# VPFE0_VPFE register map
Vendor: Texas Instruments
Peripheral module from a debugger description file (folder J7ES).
Registers are 32-bit, read-write, reset 0x0 unless marked. A register's access mark holds for its fields unless they carry their own. Offsets are as the file gives them; lines under a group give offsets from that group; [hi:lo] are bit positions; {n}, {i} and the like mark numbered series; 'fields as' and 'values as' point back to an identical list; <NAME> marks a mode.

## VPFE0_VPFE
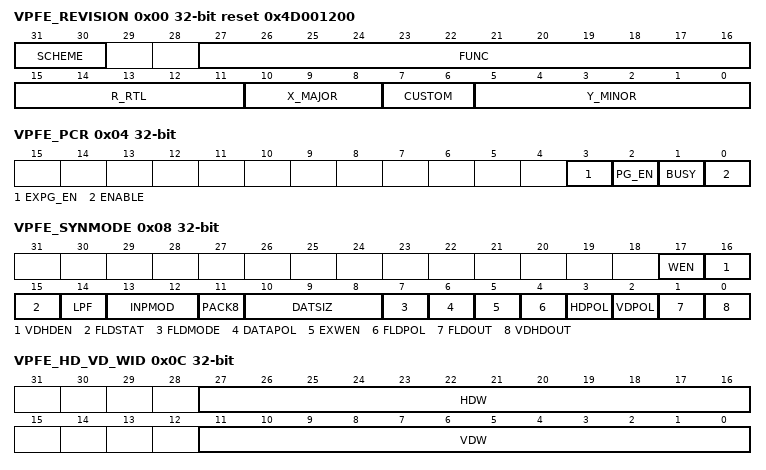
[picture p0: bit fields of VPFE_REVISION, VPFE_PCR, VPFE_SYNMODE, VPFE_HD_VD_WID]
0x00 VPFE_REVISION ro reset 0x4D001200 — IP Revision Identifier (X.Y.R) Used by software to track features, bugs, and compatibility
  [31:30] SCHEME — Used to distinguish between old scheme and current
  [27:16] FUNC — Function value
  [15:11] R_RTL — RTL Version [R], maintained by IP design owner
  [10:8] X_MAJOR — Major Revision [X], maintained by IP specification owner
  [7:6] CUSTOM — Custom version
  [5:0] Y_MINOR — Minor Revision [Y], maintained by IP specification owner
0x04 VPFE_PCR access per field — Peripheral Control Register
  [3] EXPG_EN rw — External pattern generator enable
  [2] PG_EN rw — Pattern generator enable
  [1] BUSY ro — VPFE busy bit 0h = Not busy 1h = Busy
  [0] ENABLE rw — This bit is latched by VD [start of frame] 0h = Disable 1h = Enable
0x08 VPFE_SYNMODE access per field — SYNC and Mode Set Register
  [17] WEN rw — Data write enable Controls whether or not input raw data is written to external memory This bit is latched by VD 0h = Disable 1h = Enable
  [16] VDHDEN rw — VD/HD enable Activates internal timing generator to synchronize with external VD/HD signals This bit should be set to 1 when HD and VD signals are used at any time 0h = Disable 1h = Enable
  [15] FLDSTAT ro — Field status Indicates the status of the current field when in interlaced mode 0h = Odd field 1h = Even field
  [14] LPF rw — 3-tap low-pass [anti-aliasing] filter This bit is latched by VD 0h = Off 1h = On
  [13:12] INPMOD rw — Setting data input mode 0h = Raw Data 1h = YCbCr 16 bit 2h = YCbCr 8 bit 3h = Reserved
  [11] PACK8 rw — Pack to8-bit/pixel [into external memory] 0h = Normal 16bits/pixel 1h = 8 bits/pixel
  [10:8] DATSIZ rw — CCD data width is only valid when INPMOD is set to 0 0h = 16 bits 1h = 15 bits 2h = 14 bits 3h = 13 bits 4h = 12 bits 5h = 11 bits 6h = 10 bits 7h = 8 bits
  [7] FLDMODE rw — Sensor field mode 0h = Non-interlacedn 1h = interlaced
  [6] DATAPOL rw — Input data polarity 0h = Normal 1h = Ones complement
  [5] EXWEN rw — External WEN selection When set to 1 and when VDHDEN is set to 1, the WEN signal is used as the external memory write enable [to external memory] The data is stored to memory only when the external sync [HD and VD] signals are active 0h = Do not use external WEN 1h = Use external WEN
  [4] FLDPOL rw — Field indicator polarity 0h = Positive 1h = Negative
  [3] HDPOL rw — HD sync polarity 0h = Positive 1h = Negative
  [2] VDPOL rw — VD sync polarity 0h = Positive 1h = Negative
  [1] FLDOUT rw — Field ID Direction 0h = Input 1h = Output
  [0] VDHDOUT rw — VD/HD Sync Direction 0h = Input 1h = Output
0x0C VPFE_HD_VD_WID
  [27:16] HDW — Width of HD sync pulse if output HDW+1 pixel clocks HDWIDTH is not used when HD is input, ie when VDHDOUT in SYN_MODE register is cleared to '0' *This bit field is latched by VD
  [11:0] VDW — Width of VD sync pulse if output VDW+1 lines VDWIDTH is not used when VD is input, ie when VDHDOUT in SYN_MODE register is cleared to '0' *This bit field is latched by VD
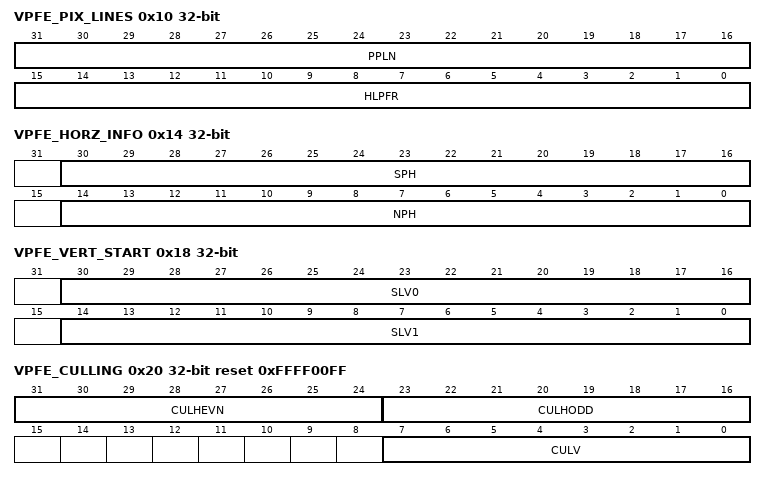
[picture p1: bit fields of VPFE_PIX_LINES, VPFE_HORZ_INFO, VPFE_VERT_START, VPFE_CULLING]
0x10 VPFE_PIX_LINES — Number of pixels in a horizontal line and number of lines in a frame
  [31:16] PPLN — Pixels per line - number of pixel clock periods in one line HD period = PPLN+1 pixel clocks PPLN is not used when HD and VD are inputs, ie when VDHDOUT in SYN_MODE register is cleared to '0' *This bit field is latched by VD
  [15:0] HLPFR — Half lines per field or frame - sets number of half lines per frame or field VD period = [HLPFR+1]/2 lines HLPFR is not used when HD and VD are inputs, ie when VDHDOUT in SYN_MODE register is cleared to '0' This tells the internal timing generator to generate the sufficient number of HD pulses in between two VD pulses If the sensor is an interlaced sensor, say for example, with a total of 525 [or 526] lines, then this field should be set to 525 [or 526] This means that 525 [or 526] half lines are written for each field If the sensor is progressive, then this register should be set to be twice the number of lines to be written For example, if sensor outputs 1024 lines, this field should be set to 2048 Therefore, for interlaced sensors, this field should be set to the total number of lines For progressive sensors, this field should be set to twice the total number of lines *This bit field is latched by VD
0x14 VPFE_HORZ_INFO — Horizontal Pixel Information Register
  [30:16] SPH — Start pixel, horizontal The SPH sets the pixel clock position at which data output to external memory begins, measured from the start of HD This bit field is latched by VD
  [14:0] NPH — Number of pixels, horizontal NPH sets the number of horizontal pixels that is output to external memory = [NPH + 1] and 0xFFF0 [ie, the number of horizontal output pixels truncates to multiples of 16] This bit field is latched by VD
0x18 VPFE_VERT_START — Vertical Line - Settings for the Starting Pixel Register
  [30:16] SLV0 — Start line, vertical [field 0] SLV0 sets line at which data output to external memory will begin, measured from the start of VD This bit field is latched by VD
  [14:0] SLV1 — Start line, vertical [field 1] SLV1 sets line at which data output to external memory will begin, measured from the start of VD For a progressive sensor this field is ignored This bit field is latched by VD
0x1C VPFE_VERT_LINES — Number of Vertical Lines Register
  [14:0] NLV — Number of lines, vertical NLV sets the number of vertical lines that will be output to external memory The number of lines output to external memory = [NLV + 1] This bit field is latched by VD
0x20 VPFE_CULLING reset 0xFFFF00FF — Culling Information in Horizontal and Vertical Directions Register
  [31:24] CULHEVN — Horizontal Culling Pattern for Even Line,8-bit mask LSB is first pixel, MSB is 8th pixel, then pattern repeats This bit field is latched by VD 0h = Culling(Deletion) 1h = Retain(to be saved in the memory)
  [23:16] CULHODD — Horizontal Culling Pattern for Odd Line,8-bit mask LSB is first pixel, MSB is 8th pixel, then pattern repeats This bit field is latched by VD 0h = Culling(Deletion) 1h = Retain(to be saved in the memory)
  [7:0] CULV — Vertical Culling Pattern,8-bit mask LSB is first line, MSB is 8th line, then pattern repeats This bit field is latched by VD 0h = Culling(Deletion) 1h = Retain(to be saved in the memory)
0x24 VPFE_HSIZE_OFF — Horizontal Size Register
  [15:0] LNOFST — Address offset for each line LNOFST Sets offset for each output line in external memory Either 16 or 32 pixels depending on setting of PACK8 the offset will be on a 32-byte boundary For optimal performance in the system, the address offset should be on a 256-byte boundary This bit field is latched by VD
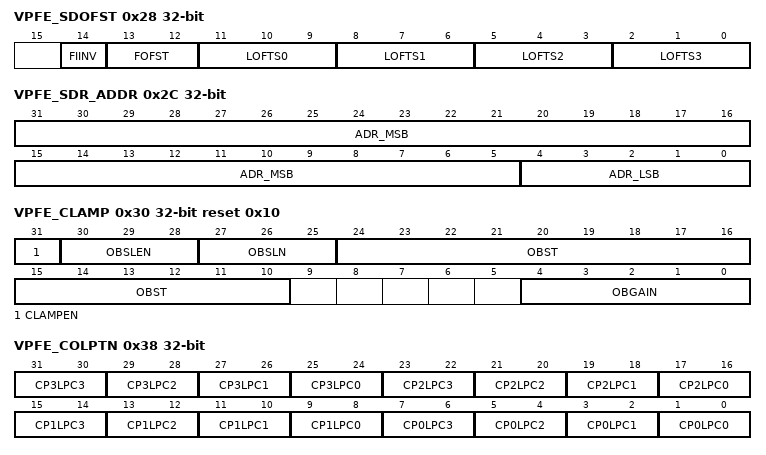
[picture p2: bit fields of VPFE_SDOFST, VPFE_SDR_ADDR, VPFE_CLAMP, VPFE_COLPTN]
0x28 VPFE_SDOFST — External Memory Line Offset Register
  [14] FIINV — Field identification signal inverse This field is latched by VD 0h = Non-inverse 1h = Inverse
  [13:12] FOFST — Line offset value of field ID = 1 This field is latched by VD 0h = +1 line 1h = +2 lines 2h = +3 lines 3h = +4 lines
  [11:9] LOFTS0 — Line offset values of even line and even field ID = 0 This field is latched by VD 0h = +1 line 1h = +2 lines 2h = +3 lines 3h = +4 lines 4h = -1 line 5h = -2 lines 6h = -3 lines 7h = -4 lines
  [8:6] LOFTS1 — Line offset values of odd line and even field ID = 0 This field is latched by VD 0h = +1 line 1h = +2 lines 2h = +3 lines 3h = +4 lines 4h = -1 line 5h = -2 lines 6h = -3 lines 7h = -4 lines
  [5:3] LOFTS2 — Line offset values of even line and odd field ID = 1 This field is latched by VD 0h = +1 line 1h = +2 lines 2h = +3 lines 3h = +4 lines 4h = -1 line 5h = -2 lines 6h = -3 lines 7h = -4 lines
  [2:0] LOFTS3 — Line offset values of odd line and odd field ID = 1 This field is latched by VD 0h = +1 line 1h = +2 lines 2h = +3 lines 3h = +4 lines 4h = -1 line 5h = -2 lines 6h = -3 lines 7h = -4 lines
0x2C VPFE_SDR_ADDR access per field — External Memory Address Register
  [31:5] ADR_MSB rw — 32-bit external memory starting address for VPFE output This bit field is latched by VD The address should be aligned on a 32-byte boundary Therefore, the 5 LSB's are ignored Furthermore, reading this register will always show the 5 LSB's as 0 For optimal performance in the system, the address should be on a 256-byte boundary
  [4:0] ADR_LSB ro — 32-bit external memory starting address for VPFE output This bit field is latched by VD The address should be aligned on a 32-byte boundary Therefore, the 5 LSB's are ignored Furthermore, reading this register will always show the 5 LSB's as 0 For optimal performance in the system, the address should be on a 256-byte boundary
0x30 VPFE_CLAMP reset 0x10 — Optical Black Clamping Setting Register
  [31] CLAMPEN — Clamp enable Enable or disable clamping of CCD data based on the calculated average of optical black samples This bit is latched by VD 0h = Disable 1h = Enable
  [30:28] OBSLEN — Optical black sample length Number of Optical Black Sample pixels per line to include in the average calculation 0h = 1 pixels 1h = 2 pixels 2h = 4 pixels 3h = 8 pixels 4h = 16 pixels 5h = Reserved 6h = Reserved 7h = Reserved
  [27:25] OBSLN — Optical black sample lines Number of Optical Black Sample lines to include in the average calculation 0h = 1 lines 1h = 2 lines 2h = 4 lines 3h = 8 lines 4h = 16 lines 5h = Reserved 6h = Reserved 7h = Reserved
  [24:10] OBST — Start pixel of optical black samples The start pixel position of optical black samples, specified from the start of HD in pixel clocks
  [4:0] OBGAIN — Gain to apply to the optical black average Multiply the optical black average with the specified gain 1Fh = 1 + 15/16 1Eh = 1 + 14/16 ..= .. 10h = 1 + 0/16 0Fh = 0 + 15/16 0Eh = 0 + 14/16 0Dh = 0 + 13/16 .. = .. 02h = 0 + 2/16 01h = 0 + 1/16 00h = 0 + 0/16
0x34 VPFE_DCSUB — DC Clamp Register
  [13:0] DCSUB — DC level to subtract from CCD data The DC value set here is subtracted from the CCD data when OBS clamping is disabled - CLAMPCLAMPEN
0x38 VPFE_COLPTN — CCD Color Pattern Register
  [2n+25:2n+24] CP3LPC{n} (n=0..3) — Color Pattern for 3rd Line, Pixel counter = {n} 0h = R/Ye 1h = Gr/Cy 2h = Gb/G 3h = B/Mg
  [2n+17:2n+16] CP2LPC{n} (n=0..3) — Color Pattern for 2nd Line, Pixel counter = {n} 0h = R/Ye 1h = Gr/Cy 2h = Gb/G 3h = B/Mg
  [2n+9:2n+8] CP1LPC{n} (n=0..3) — Color Pattern for 1st Line, Pixel counter = {n} 0h = R/Ye 1h = Gr/Cy 2h = Gb/G 3h = B/Mg
  [2n+1:2n] CP0LPC{n} (n=0..3) — Color Pattern for 0th Line, Pixel counter = {n} 0h = R/Ye 1h = Gr/Cy 2h = Gb/G 3h = B/Mg
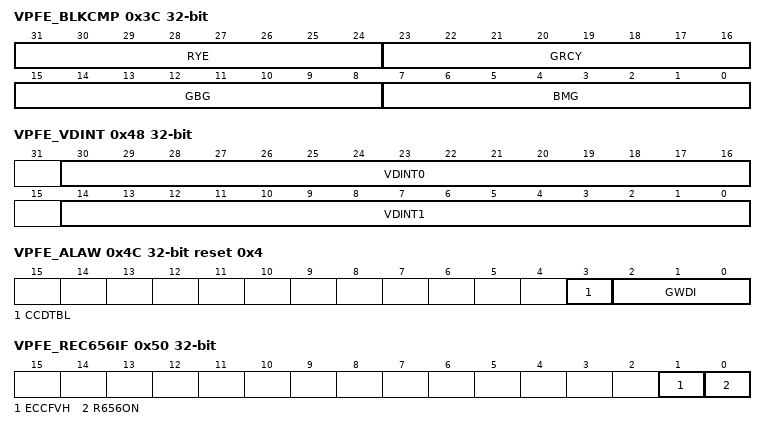
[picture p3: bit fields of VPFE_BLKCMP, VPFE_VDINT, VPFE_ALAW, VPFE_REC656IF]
0x3C VPFE_BLKCMP — Black Compensation Register
  [31:24] RYE — Black level compensation for R/Ye pixels [-128:+127] 2's complement, MSB is sign bit
  [23:16] GRCY — Black level compensation for Gr/Cy pixels [-128:+127] 2's complement, MSB is sign bit
  [15:8] GBG — Black level compensation for Gb/G pixels [-128:+127] 2's complement, MSB is sign bit
  [7:0] BMG — Black level compensation for B/Mg pixels [-128:+127] 2's complement, MSB is sign bit
0x48 VPFE_VDINT — VPFE Interrupt Control Register
  [30:16] VDINT0 — CCDC_VD0_INT interrupt timing Specify VDINT0 in units of horizontal lines from the start of VD pulse Resulting value is VDINT0+1 Note that if the rising edge [or falling edge if programmed] of the HD lines up with the rising edge [or falling edge if programmed] of VD, the 1st HD is not counted
  [14:0] VDINT1 — CCDC_VD1_INT interrupt timing Specify VDINT1 in units of horizontal lines from the start of VD pulse Resulting value is VDINT1+1 Note that if the rising edge [or falling edge if programmed] of the HD lines up with the rising edge [or falling edge if programmed] of VD, the 1st HD is not counted
0x4C VPFE_ALAW reset 0x4 — Configuration Register
  [3] CCDTBL — Apply Gamma [A-LAW] to VPFE data saved to external memory 0h = Disable 1h = Enable
  [2:0] GWDI — A-law Width Input [A-LAW table] 0h = Bits15-6 1h = Bits 14-5 2h = Bits 13-4 3h = Bits 12-3 4h = Bits 11-2 5h = Bits 10-1 6h = Bits 9-0
0x50 VPFE_REC656IF — Configuration Register
  [1] ECCFVH — FVH error correction enable 0h = Disable 1h = Enable
  [0] R656ON — REC656 interface enable 0h = Disable 1h = Enable
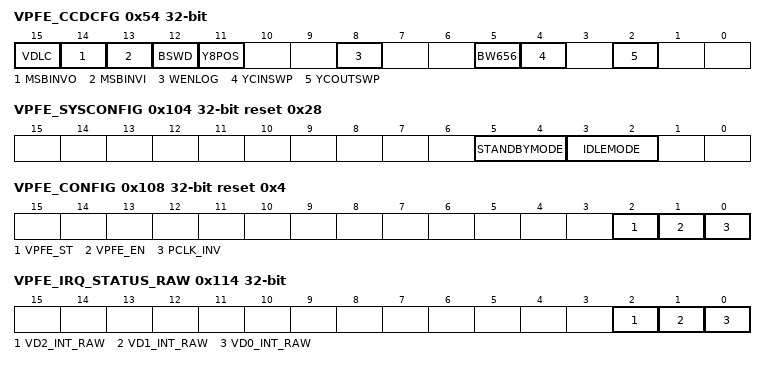
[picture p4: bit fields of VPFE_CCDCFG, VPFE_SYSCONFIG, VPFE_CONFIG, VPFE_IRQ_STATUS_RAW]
0x54 VPFE_CCDCFG — CCD Configuration Register
  [15] VDLC — Enable latching function registers on internal VSYNC If this bit is set, all the register fields that are VSYNC latched will take on new value immediately Care should be taken not to alter fields that can cause undesired behavior to the output data 0h = Latched on VSYNC 1h = Not latched on VSYNC
  [14] MSBINVO — MSB of Chroma signal output inverted 0h = Normal 1h = MSB inverted
  [13] MSBINVI — MSB of Chroma input signal stored to SDRAM inverted 0h = Normal 1h = MSB inverted
  [12] BSWD — Byte Swap Data stored to SDRAM 0h = Normal 1h = Swap bytes
  [11] Y8POS — Location of Y signal when YCbCr 8bit data is input 0h = Even pixel 1h = Odd pixel
  [8] WENLOG — Specifies CCD valid area 0h = Internal valid signal WEN signal is ANDed logically and 1h = Internal valid signal and WEN signal is ORed logically
  [5] BW656 — The data width in CCIR656 input mode 0h = 8 bits 1h = 10 bits
  [4] YCINSWP — Y input [YIN[7:0]] and C input [CIN[7:0]] are swapped
  [2] YCOUTSWP — Y output [YOUT[7:0]] and C output [COUT[7:0]] are swapped
0x98 VPFE_DMA_CNTL access not given — DMA Status and Control
  [31] OVERFLOW — DMA Overflow Flag Flag bit that is set when data is dropped due to a delay in writing data out the DMA interface This bit remains set until a 1 is written by software 0h = No overflow has occured 1h = Overflow has occured (access RW1C)
0x104 VPFE_SYSCONFIG reset 0x28 — Clock management configuration
  [5:4] STANDBYMODE — Configuration of the local initiator state management mode By definition, initiator may generate read/write transaction as long as it is out of STANDBY state 0h = Force Standby mode, local initiator is unconditionally placed in standby state.Backup mode, for debug only 1h = No Standby mode, local initiator is unconditionally placed out of standby state. Backup mode, for debug only 2h = Smart Standby mode, local initiator standby status depends on local conditions. IP module shall not generate wakeup events 3h = Smart Standby wakeup capable mode, local initiator standby status depends on local conditions. IP module may generate wakeup events when in standby state. Mode is only relevant if the appropriate IP module mwakeup output is implemented
  [3:2] IDLEMODE — Configuration of the local target state management mode By definition, target can handle read/write transaction as long as it is out of IDLE state 0h = Force Idle mode, local targets idle state follows the systems idle requests unconditionally, regardless of the IP modules internal requirements.Backup mode, for debug only 1h = No idle mode, local target never enters idle state. Backup mode, for debug only 2h = Smart Idle mode, local targets idle eventually follows the systems idle requests, depends on the IP modules internal requirements. IP module shall not generate wakeup events 3h = Smart idle wakeup capable mode, local targets idle state eventually follows the systems idle requests, depending on the IP modules internal requirements. IP module may generate wakeup events when in idle state. Mode is only relevant if the appropriate IP module mwakeup output is implemented
0x108 VPFE_CONFIG access per field reset 0x4 — Module configuration register
  [2] VPFE_ST ro — VPFE Master OCP interface Status 0h = OCP master interface is avctive 1h = OCP master interface is in standby mode
  [1] VPFE_EN rw — VPFE Master OCP interface enable Software can has to use this bit to enable/disable the VPFE master OCP interface When the master OCP interface is disabled, it is placed in Standby mode Standby mode can also be entered by using the right setting on the STANDBYMODE field in theVPFE_SYSCONFIG register 0h = Disable VPFE master OCP interface 1h = Enable VPFE master OCP interface
  [0] PCLK_INV rw — Pixel clock inversion enable 0h = Pixel clock is not inverted, data is sampled on the rising edge of the clock 1h = pixel clock is inverted, data is sampled on the falling edge of the clock
0x110 VPFE_IRQ_EOI access not given — Module EOI register The EOI register is used to re-trigger the pulse interrupt signal to ensure that any nested interrupt events are serviced. The software interrupt handler must write to the EOI register at the end of the current interrupt processing routine, so that new events can re-trigger the pulse interrupt signal again. For level interrupt signals the EOI register is not functional and must not be used.
  [0] EOI — EOI for VPFE This register allows software to acknowledge the completion of an interrupt When this register is written, an eoi_write signal is generated internal to the module and another interrupt will be triggered if the interrupt sources are still present The register will clear itself one cycle after it is written (access RW1C)
0x114 VPFE_IRQ_STATUS_RAW access not given — Interrupt raw status register
  [2] VD2_INT_RAW — CCDC VD2 interrupt status raw value - A read value of 1 from this register indicates that the VD2 interrupt status is1 - When the read value is 0, software can write the value to 1 to set the interrupt - Writing a 0 to this bit has no effect (access RW1S)
  [1] VD1_INT_RAW — CCDC VD1 interrupt status raw value - A read value of 1 from this register indicates that the VD1 interrupt status is1 - When the read value is 0, software can write the value to 1 to set the interrupt - Writing a 0 to this bit has no effect (access RW1S)
  [0] VD0_INT_RAW — CCDC VD0 interrupt status raw value - A read value of 1 from this register indicates that the VD0 interrupt status is1 - When the read value is 0, software can write the value to 1 to set the interrupt - Writing a 0 to this bit has no effect (access RW1S)
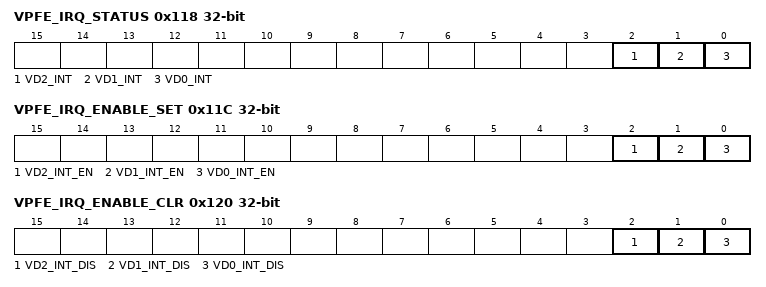
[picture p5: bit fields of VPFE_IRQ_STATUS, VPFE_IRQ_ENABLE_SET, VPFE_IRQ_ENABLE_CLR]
0x118 VPFE_IRQ_STATUS access not given — Interrupt status register
  [2] VD2_INT — CCDC VD2 interrupt status value - A read value of 1 from this register indicates that the VD2 interrupt status is 1, if it is enabled - When the read value is 1, software can write a 1 to clear the interrupt - Writing a 0 to this bit has no effect (access RW1C)
  [1] VD1_INT — CCDC VD1 interrupt status value - A read value of 1 from this register indicates that the VD2 interrupt status is 1, if it is enabled - When the read value is 1, software can write a 1 to clear the interrupt - Writing a 0 to this bit has no effect (access RW1C)
  [0] VD0_INT — CCDC VD0 interrupt status value - A read value of 1 from this register indicates that the VD2 interrupt status is 1, if it is enabled - When the read value is 1, software can write a 1 to clear the interrupt - Writing a 0 to this bit has no effect (access RW1C)
0x11C VPFE_IRQ_ENABLE_SET access not given — Interrupt enable set
  [2] VD2_INT_EN — CCDC VD2 interrupt enable - Write 1 to enable this interrupt - Write 0 has no effect - Read 1 indicates interrupt is enabled - Read 0 indicates interrupt is not enabled (access RW1S)
  [1] VD1_INT_EN — CCDC VD1 interrupt enable - Write 1 to enable this interrupt - Write 0 has no effect - Read 1 indicates interrupt is enabled - Read 0 indicates interrupt is not enabled (access RW1S)
  [0] VD0_INT_EN — CCDC VD0 interrupt enable - Write 1 to enable this interrupt - Write 0 has no effect - Read 1 indicates interrupt is enabled - Read 0 indicates interrupt is not enabled (access RW1S)
0x120 VPFE_IRQ_ENABLE_CLR access not given — Interrupt enable clear
  [2] VD2_INT_DIS — CCDC VD2 interrupt disable - Write 1 to disable this interrupt - Write 0 has no effect - Read 1 indicates interrupt is enabled - Read 0 indicates interrupt is not enabled (access RW1C)
  [1] VD1_INT_DIS — CCDC VD1 interrupt disable - Write 1 to disable this interrupt - Write 0 has no effect - Read 1 indicates interrupt is enabled - Read 0 indicates interrupt is not enabled (access RW1C)
  [0] VD0_INT_DIS — CCDC VD0 interrupt disable - Write 1 to disable this interrupt - Write 0 has no effect - Read 1 indicates interrupt is enabled - Read 0 indicates interrupt is not enabled (access RW1C)
